# Test register map
Vendor: zermio; File version: 0.1
Single-core RISC-V processor, 1 x I2C
CPU: reis-riscv r0p1, little endian, no MPU, no FPU, VTOR, 2 interrupt priority bits, 1 interrupts
Registers are 32-bit, read-write, reset 0x0 unless marked. A register's access mark holds for its fields unless they carry their own. Offsets are from the block's base; lines under a group give offsets from that group; [hi:lo] are bit positions; {n}, {i} and the like mark numbered series; 'fields as' and 'values as' point back to an identical list; <NAME> marks a mode.

## Memory map
0x40014000 IO_BANK0 size 0x1000
0x80040000 TIMER0 size 0x1000 — Controls timer
0x80200000 I2C0 size 0x1000 — I2C interface for host and device mode, supporting up to 1 Mbaud data rates
0x80200100 I2C1 size 0x1000
0x80400100 TIMER1 size 0x1000

## Interrupts
2 Event IRQ (I2C0)
3 Error IRQ (I2C0)
3 Event IRQ (I2C1)
10 Finish IRQ (TIMER0, TIMER1)
13 IO_IRQ_BANK0 (IO_BANK0)

## TIMER0 — Controls timer
Base 0x80040000
0x00 MTIMEL — mtime low
  [31:0] VALUE
0x04 MTIMEH — mtime high
  [31:0] VALUE
0x08 MTIMECMPL — mtime cmp low
  [31:0] VALUE
0x0C MTIMECMPH — mtime cmp high
  [31:0] VALUE

## TIMER1
Base 0x80400100
0x00 MTIMEL 17-bit — mtime low
  [31:0] VALUE
0x04 MTIMEH 17-bit — mtime high
  [31:0] VALUE
0x08 MTIMECMPL 17-bit — mtime cmp low
  [31:0] VALUE
0x0C MTIMECMPH 17-bit — mtime cmp high
  [31:0] VALUE

## IO_BANK0
Base 0x40014000
{0x0+8i} GPIO{i} (i=0..29) group — Cluster GPIO{i}, containing GPIO*_STATUS, GPIO*_CTRL
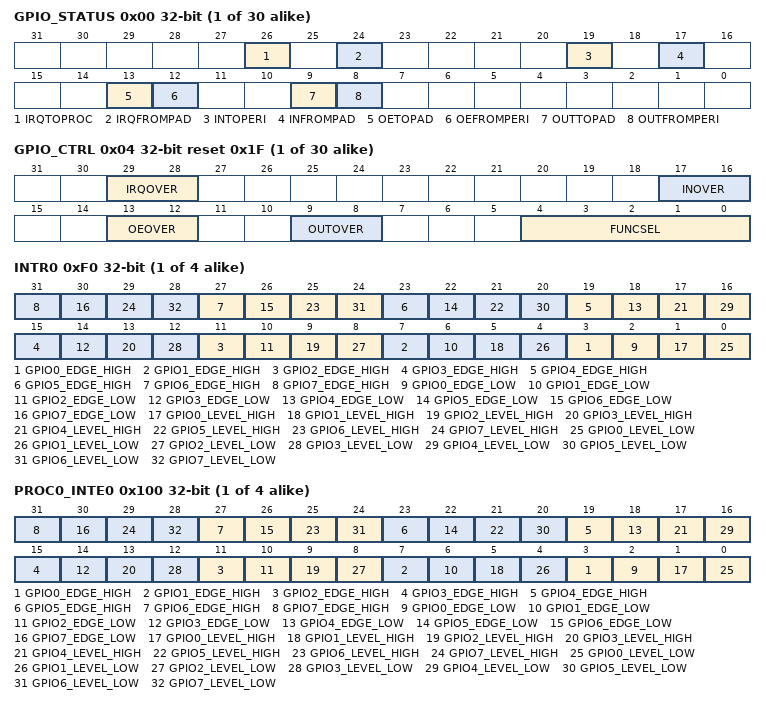
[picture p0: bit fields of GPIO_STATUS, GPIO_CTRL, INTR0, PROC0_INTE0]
  0x00 GPIO_STATUS ro
    [26] IRQTOPROC — interrupt to processors, after override is applied
    [24] IRQFROMPAD — interrupt from pad before override is applied
    [19] INTOPERI — input signal to peripheral, after override is applied
    [17] INFROMPAD — input signal from pad, before override is applied
    [13] OETOPAD — output enable to pad after register override is applied
    [12] OEFROMPERI — output enable from selected peripheral, before register override is applied
    [9] OUTTOPAD — output signal to pad after register override is applied
    [8] OUTFROMPERI — output signal from selected peripheral, before register override is applied
  0x04 GPIO_CTRL reset 0x1F — GPIO control including function select and overrides.
    [29:28] IRQOVER
      0=NORMAL (don't invert the interrupt); 1=INVERT (invert the interrupt); 2=LOW (drive interrupt low); 3=HIGH (drive interrupt high)
    [17:16] INOVER
      0=NORMAL (don't invert the peri input); 1=INVERT (invert the peri input); 2=LOW (drive peri input low); 3=HIGH (drive peri input high)
    [13:12] OEOVER
      0=NORMAL (drive output enable from peripheral signal selected by funcsel); 1=INVERT (drive output enable from inverse of peripheral signal selected by funcsel); 2=DISABLE (disable output); 3=ENABLE (enable output)
    [9:8] OUTOVER
      0=NORMAL (drive output from peripheral signal selected by funcsel); 1=INVERT (drive output from inverse of peripheral signal selected by funcsel); 2=LOW (drive output low); 3=HIGH (drive output high)
    [4:0] FUNCSEL — 0-31 -> selects pin function according to the GPIO table. Not all options are valid for all GPIO pins.
      0=jtag (Connect to JTAG peripheral); 1=spi (Connect to matching SPI peripheral); 2=uart (Connect to matching UART peripheral); 3=i2c (Connect to matching I2C peripheral); 4=pwm (Connect to matching PWM peripheral); 5=sio (Use as a GPIO pin (connect to SIO peripheral)); 6=pio0 (Connect to PIO0 peripheral); 7=pio1 (Connect to PIO1 peripheral); 8=clock (Connect to Clock peripheral); 9=usb (Connect to USB peripheral); 31=null (Connect to nothing)
{0xF0+4i} INTR{i} (i=0..3) access per field — Raw Interrupts
  [4n+3] GPIO{n}_EDGE_HIGH rw write-1-clears (n=0..7), [4n+2] GPIO{n}_EDGE_LOW rw write-1-clears (n=0..7), [4n+1] GPIO{n}_LEVEL_HIGH ro (n=0..7), [4n] GPIO{n}_LEVEL_LOW ro (n=0..7)
{0x100+4i} PROC0_INTE{i} (i=0..3) — Interrupt Enable for proc0
  [4n+3] GPIO{n}_EDGE_HIGH (n=0..7), [4n+2] GPIO{n}_EDGE_LOW (n=0..7), [4n+1] GPIO{n}_LEVEL_HIGH (n=0..7), [4n] GPIO{n}_LEVEL_LOW (n=0..7)
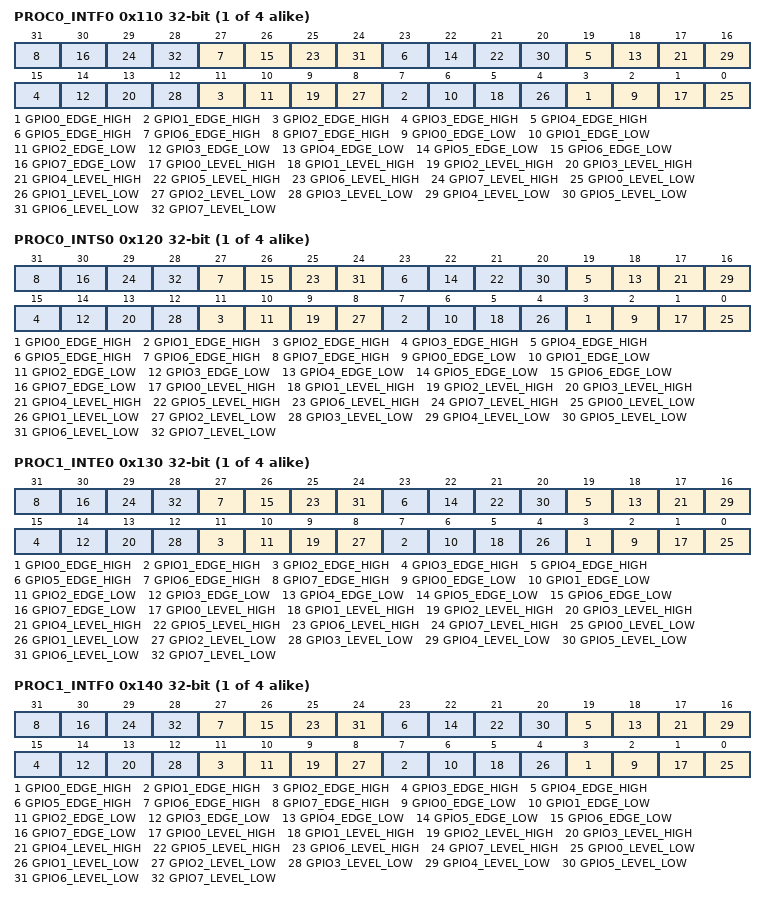
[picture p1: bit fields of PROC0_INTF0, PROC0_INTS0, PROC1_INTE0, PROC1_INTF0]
{0x110+4i} PROC0_INTF{i} (i=0..3) — Interrupt Force for proc0
  fields as PROC0_INTE0
{0x120+4i} PROC0_INTS{i} (i=0..3) ro — Interrupt status after masking & forcing for proc0
  fields as PROC0_INTE0
{0x130+4i} PROC1_INTE{i} (i=0..3) — Interrupt Enable for proc1
  fields as PROC0_INTE0
{0x140+4i} PROC1_INTF{i} (i=0..3) — Interrupt Force for proc1
  fields as PROC0_INTE0
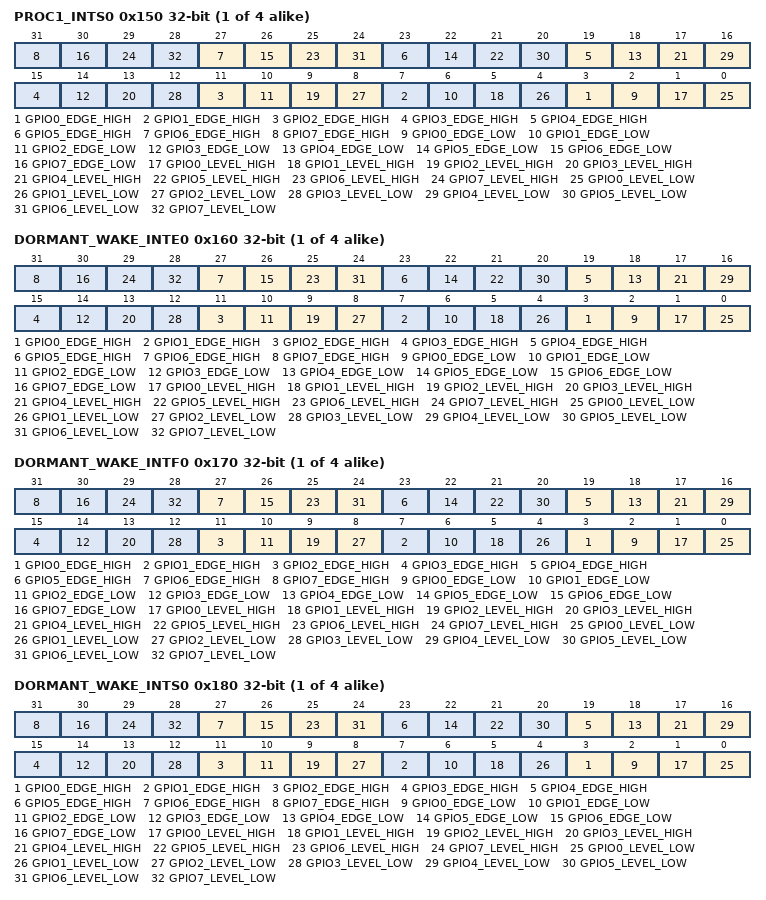
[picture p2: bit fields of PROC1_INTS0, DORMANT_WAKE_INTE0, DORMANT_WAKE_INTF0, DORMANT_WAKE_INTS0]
{0x150+4i} PROC1_INTS{i} (i=0..3) ro — Interrupt status after masking & forcing for proc1
  fields as PROC0_INTE0
{0x160+4i} DORMANT_WAKE_INTE{i} (i=0..3) — Interrupt Enable for dormant_wake
  fields as PROC0_INTE0
{0x170+4i} DORMANT_WAKE_INTF{i} (i=0..3) — Interrupt Force for dormant_wake
  fields as PROC0_INTE0
{0x180+4i} DORMANT_WAKE_INTS{i} (i=0..3) ro — Interrupt status after masking & forcing for dormant_wake
  fields as PROC0_INTE0
